# cyt2cl register map
Vendor: Cypress Semiconductor; Series: cyt2cl; File version: 1.0
CPU: CM4 r0p1, little endian, MPU, FPU, VTOR, 3 interrupt priority bits
Registers are 32-bit, read-write, reset 0x0 unless marked. A register's access mark holds for its fields unless they carry their own. Offsets are from the block's base; [hi:lo] are bit positions; lines under a group give offsets from that group; 'fields as' and 'values as' point back to an identical list.

## FLASHC — Flash controller
Base 0x40240000
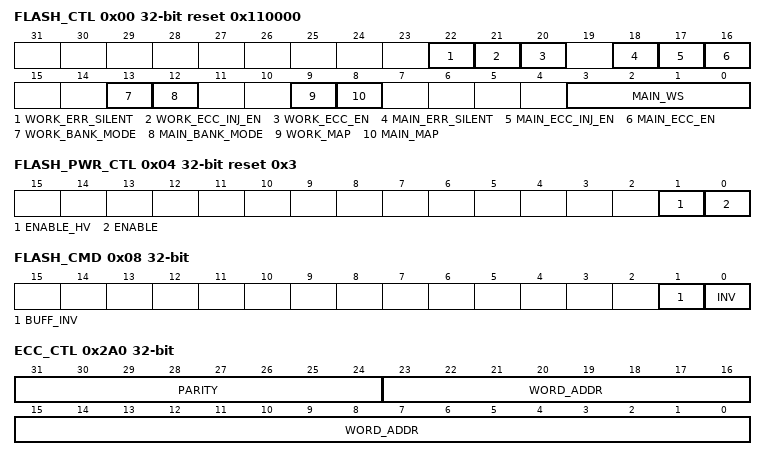
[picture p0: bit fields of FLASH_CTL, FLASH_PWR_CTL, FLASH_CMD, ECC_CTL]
0x00 FLASH_CTL reset 0x110000 — Control
  [22] WORK_ERR_SILENT — Specifies bus transfer behavior for a non-recoverable error on the FLASH macro work interface (either a non-correctable ECC error, a FLASH macro work interface internal error, a FLASH macro work interface memory hole access): 0: Bus transfer has a bus error. 1: Bus transfer does NOT have a bus error; i.e. the error is 'silent' In either case, the erroneous FLASH macro data is returned by the bus master interface. The erroneous data is NOT placed in a bus master interface's cache and/or buffer. This field is ONLY used by CPU (and debug i.e. SYS_AP/CM0_AP/CM4_AP) bus transfers. Non-CPU bus transfers always have a bus transfer with a bus error, in case of a non-recoverable error. Note: All CPU bus masters have dedicated status registers (CM0_STATUS and CM4_STATUS) to register the occurrence of FLASH macro work interface internal errors (non-correctable ECC errors and memory hole errors are NOT registered). Note: fault reporting can be used to identify the error that occurred: - FLASH macro work interface internal error. - FLASH macro work interface non-recoverable ECC error. - FLASH macro work interface recoverable ECC error. - FLASH macro work interface memory hole error.
  [21] WORK_ECC_INJ_EN — Enable error injection for FLASH work interface. When'1', the parity (ECC_CTL.PARITY[6:0]) is used for a load from the ECC_CTL.WORD_ADDR[23:0] word address.
  [20] WORK_ECC_EN — Enable ECC checking for FLASH work interface: 0: Disabled. ECC checking/reporting on FLASH work interface is disabled. No correctable or non-correctable faults are reported. 1: Enabled.
  [18] MAIN_ERR_SILENT — Specifies bus transfer behavior for a non-recoverable error on the FLASH macro main interface (either a non-correctable ECC error, a FLASH macro main interface internal error, a FLASH macro main interface memory hole access): 0: Bus transfer has a bus error. 1: Bus transfer does NOT have a bus error; i.e. the error is 'silent' In either case, the erroneous FLASH macro data is returned by the bus master interface. The erroneous data is NOT placed in a bus master interface's cache and/or buffer. This field is ONLY used by CPU (and debug i.e. SYS_AP/CM0_AP/CM4_AP) bus transfers. Non-CPU bus transfers always have a bus transfer with a bus error, in case of a non-recoverable error. Note: All CPU bus masters have dedicated status registers (CM0_STATUS and CM4_STATUS) to register the occurrence of FLASH macro main interface internal errors (non-correctable ECC errors and memory hole errors are NOT registered). Note: fault reporting can be used to identify the error that occurred: - FLASH macro main interface internal error. - FLASH macro main interface non-recoverable ECC error. - FLASH macro main interface recoverable ECC error. - FLASH macro main interface memory hole error.
  [17] MAIN_ECC_INJ_EN — Enable error injection for FLASH main interface. When'1', the parity (ECC_CTL.PARITY[7:0]) is used for a load from the ECC_CTL.WORD_ADDR[23:0] word address.
  [16] MAIN_ECC_EN — Enable ECC checking for FLASH main interface: 0: Disabled. ECC checking/reporting on FLASH main interface is disabled. No correctable or non-correctable faults are reported. 1: Enabled.
  [13] WORK_BANK_MODE — Specifies bank mode of FLASH macro work array. 0: Single bank mode. 1: Dual bank mode.
  [12] MAIN_BANK_MODE — Specifies bank mode of FLASH macro main array. 0: Single bank mode. 1: Dual bank mode.
  [9] WORK_MAP — Specifies mapping of FLASH macro work array. 0: Mapping A. 1: Mapping B. This field is only used when WORK_BANK_MODE is '1' (dual bank mode).
  [8] MAIN_MAP — Specifies mapping of FLASH macro main array. 0: Mapping A. 1: Mapping B. This field is only used when MAIN_BANK_MODE is '1' (dual bank mode).
  [3:0] MAIN_WS — FLASH macro main interface wait states: '0': 0 wait states. ... '15': 15 wait states
0x04 FLASH_PWR_CTL reset 0x3 — Flash power control
  [1] ENABLE_HV — Enables HV power to the flash memory
  [0] ENABLE — Enables power to the flash memory
0x08 FLASH_CMD — Command
  [1] BUFF_INV — Invalidation of ALL buffers (does not invalidate the caches). SW writes a '1' to clear the buffers. HW sets this field to '0' when the operation is completed. The operation takes a maximum of three clock cycles on the slowest of the clk_slow and clk_fast clocks. Note: the caches only capture FLASH macro main array data. Therefore, invalidating just the buffers (BUFF_INV) does not invalidate captures main array data in the caches.
  [0] INV — Invalidation of ALL caches (for CM0+ and CM4) and ALL buffers. SW writes a '1' to clear the caches. HW sets this field to '0' when the operation is completed. The operation takes a maximum of three clock cycles on the slowest of the clk_slow and clk_fast clocks. The caches' LRU structures are also reset to their default state.
0x2A0 ECC_CTL — ECC control
  [31:24] PARITY — ECC parity to use for ECC error injection at address WORD_ADDR. - For cache SRAM ECC, the 7-bit parity PARITY[6:0] is for a 32-bit word. - For FLASH main interface ECC, the 8-bit parity PARITY[7:0] is for a 64-bit word. - For FLASH work interface ECC, the 7-bit parity PARITY[6:0] is for a 32-bit word.
  [23:0] WORD_ADDR — Specifies the word address where an error will be injected. - For cache SRAM ECC, the word address WORD_ADDR[23:0] is device address A[25:2]. On a FLASH macro refill to this word address and when the corresponding CM0/4_CA_CTL.RAM_ECC_INJ_EN bit is '1', the parity (PARITY[6:0]) is injected and stored in the cache. - For FLASH main interface ECC, the word address WORD_ADDR[23:0] is device address A[26:3]. On a FLASH main interface read and when FLASH_CTL.MAIN_ECC_INJ_EN bit is '1', the parity (PARITY[7:0]) replaces the FLASH macro parity (FLASH main interface read path is manipulated). - For FLASH work interface ECC, the word address WORD_ADDR[23:0] is device address A[24:2]. On a FLASH work interface read and when FLASH_CTL.WORK_ECC_INJ_EN bit is '1', the parity (PARITY[6:0]) replaces the FLASH macro parity (FLASH work interface read path is manipulated).
0x2B0 FM_SRAM_ECC_CTL0 — eCT Flash SRAM ECC control 0
  [31:0] ECC_INJ_DATA — 32-bit data for ECC error injection test of eCT Flash SRAM ECC logic.
0x2B4 FM_SRAM_ECC_CTL1 — eCT Flash SRAM ECC control 1
  [6:0] ECC_INJ_PARITY — 7-bit parity for ECC error injection test of eCT Flash SRAM ECC logic.
0x2B8 FM_SRAM_ECC_CTL2 ro — eCT Flash SRAM ECC control 2
  [31:0] CORRECTED_DATA — 32-bit corrected data output of the ECC syndrome logic.
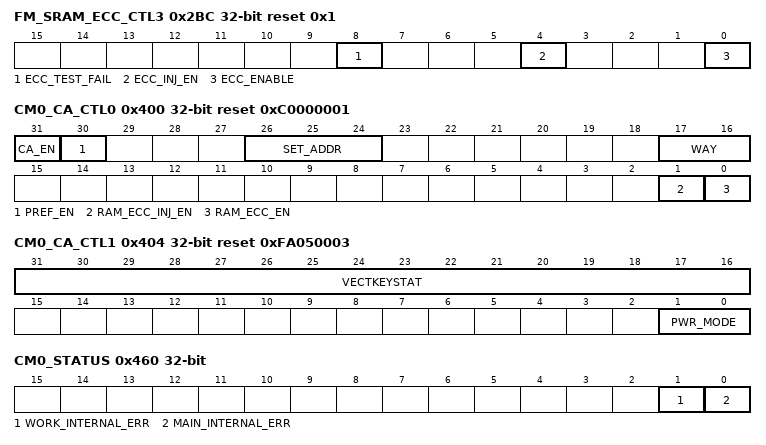
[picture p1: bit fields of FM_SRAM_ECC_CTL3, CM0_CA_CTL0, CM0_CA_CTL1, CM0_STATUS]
0x2BC FM_SRAM_ECC_CTL3 reset 0x1 — eCT Flash SRAM ECC control 3
  [8] ECC_TEST_FAIL ro — Status of ECC test. 1 : ECC test failed because eCT Flash macro is busy and using the SRAM. 0: ECC was performed.
  [4] ECC_INJ_EN — eCT Flash SRAM ECC error injection test enable. Follow the steps below for ECC logic test: 1. Write corrupted or uncorrupted 39-bit data to FM_SRAM_ECC_CTL0/1 registers. 2. Set the ECC_INJ_EN bit to '1'. 3. Confirm that the bit ECC_TEST_FAIL is '0'. If this is not the case, start over at item 1 because the eCT Flash was not idle. 4. Check the corrected data in FM_SRAM_ECC_CTL2. 5. Confirm that fault was reported to fault structure, and check syndrome (only applicable if corrupted data was written in step 1). 6. If not finished, start over at 1 with different data.
  [0] ECC_ENABLE — ECC generation/check enable for eCT Flash SRAM memory.
0x400 CM0_CA_CTL0 reset 0xC0000001 — CM0+ cache control
  [31] CA_EN — Cache enable: 0: Disabled. The cache tag valid bits are reset to '0's and the cache LRU information is set to '1's (making way 0 the LRU way and way 3 the MRU way). 1: Enabled.
  [30] PREF_EN — Prefetch enable: 0: Disabled. 1: Enabled. Prefetching requires the cache to be enabled; i.e. ENABLED is '1'.
  [26:24] SET_ADDR — Specifies the cache set for which cache information is provided in CM0_CA_STATUS0/1/2.
  [17:16] WAY — Specifies the cache way for which cache information is provided in CM0_CA_STATUS0/1/2.
  [1] RAM_ECC_INJ_EN — Enable error injection for cache. When '1', the parity (ECC_CTL.PARITY[6:0]) is used when a refill is done from the FLASH macro to the ECC_CTL.WORD_ADDR[23:0] word address.
  [0] RAM_ECC_EN — Enable ECC checking for cache accesses: 0: Disabled. 1: Enabled.
0x404 CM0_CA_CTL1 reset 0xFA050003 — CM0+ cache control
  [31:16] VECTKEYSTAT ro — Register key (to prevent accidental writes). - Should be written with a 0x05fa key value for the write to take effect. - Always reads as 0xfa05. Note: Although the SW attribute for this field says ''R', SW need to write the key 0x05fa in this field for this register write to happen. This is a built in protection provided to prevent accidental writes from SW.
  [1:0] PWR_MODE — Specifies power mode for CM0 cache. The following sequnece should be followed for turning OFF/ON the cache SRAM. Turn OFF sequence: a) Write CM0_CA_CTL0 to disable cache. b) Write CM0_CA_CTL1 to turn OFF cache SRAM. Turn ON sequence: a) Write CM0_CA_CTL1 to turn ON cache SRAM. b) Delay to allow power up of cache SRAM. Delay should be at a minimum of CM0_CA_CTL2.PWRUP_DELAY CLK_SLOW clock cycles. c) Write CM0_CA_CTL0 to enable cache.
    0=OFF (Power OFF the CM0 cache, no retain); 1=RSVD (Undefined); 2=RETAINED (Put the CM0 cache in retained mode); 3=ENABLED (Enable/Turn ON the CM0 cache SRAM.)
0x408 CM0_CA_CTL2 reset 0x12C — CM0+ cache control
  [9:0] PWRUP_DELAY — Number clock cycles delay needed after power domain power up
0x440 CM0_CA_STATUS0 ro — CM0+ cache status 0
  [31:0] VALID32 — Sixteen valid bits of the cache line specified by CM0_CA_CTL.WAY and CM0_CA_CTL.SET_ADDR.
0x444 CM0_CA_STATUS1 ro reset not defined — CM0+ cache status 1
  [31:0] TAG — Cache line address of the cache line specified by CM0_CA_CTL.WAY and CM0_CA_CTL.SET_ADDR.
0x448 CM0_CA_STATUS2 ro reset not defined — CM0+ cache status 2
  [5:0] LRU — Six bit LRU representation of the cache set specified by CM0_CA_CTL.SET_ADDR. The encoding of the field is as follows ('X_LRU_Y' indicates that way X is Less Recently Used than way Y): Bit 5: 0_LRU_1: way 0 less recently used than way 1. Bit 4: 0_LRU_2. Bit 3: 0_LRU_3. Bit 2: 1_LRU_2. Bit 1: 1_LRU_3. Bit 0: 2_LRU_3.
0x460 CM0_STATUS — CM0+ interface status
  [1] WORK_INTERNAL_ERR — See CM0_STATUS.MAIN_INTERNAL_ERROR.
  [0] MAIN_INTERNAL_ERR — Specifies/registers the occurrence of a FLASH macro main interface internal error (typically the result of a read access while a program erase operation is ongoing) as a result of a CM0+ access (or debug access via SYS_AP/CM0_AP). SW clears this field to '0'. HW sets this field to '1' on a FLASH macro main interface internal error. Typically, SW reads this field after a code section to detect the occurrence of an error. Note: this field is independent of FLASH_CTL.MAIN_ERR_SILENT.
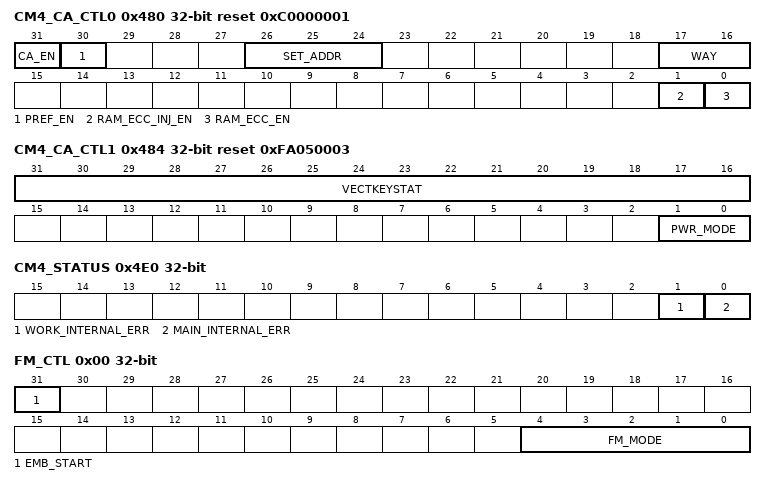
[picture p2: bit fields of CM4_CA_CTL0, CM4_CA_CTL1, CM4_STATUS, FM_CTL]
0x480 CM4_CA_CTL0 reset 0xC0000001 — CM4 cache control
  [31] CA_EN — Cache enable: 0: Disabled. The cache tag valid bits are reset to '0's and the cache LRU information is set to '1's (making way 0 the LRU way and way 3 the MRU way). 1: Enabled.
  [30] PREF_EN — Prefetch enable: 0: Disabled. 1: Enabled. Prefetching requires the cache to be enabled; i.e. ENABLED is '1'.
  [26:24] SET_ADDR — Specifies the cache set for which cache information is provided in CM4_CA_STATUS0/1/2.
  [17:16] WAY — Specifies the cache way for which cache information is provided in CM4_CA_STATUS0/1/2.
  [1] RAM_ECC_INJ_EN — See CM0_CA_CTL.
  [0] RAM_ECC_EN — See CM0_CA_CTL.
0x484 CM4_CA_CTL1 reset 0xFA050003 — CM4 cache control
  [31:16] VECTKEYSTAT ro — Register key (to prevent accidental writes). - Should be written with a 0x05fa key value for the write to take effect. - Always reads as 0xfa05. Note: Although the SW attribute for this field says ''R', SW need to write the key 0x05fa in this field for this register write to happen. This is a built in protection provided to prevent accidental writes from SW.
  [1:0] PWR_MODE — Specifies power mode for CM4 cache. The following sequnece should be followed for truning OFF/ON the cache SRAM. Turn OFF sequence: a) Write CM4_CA_CTL0 to disable cache. b) Write CM4_CA_CTL1 to turn OFF cache SRAM. Turn ON sequence: a) Write CM4_CA_CTL1 to turn ON cache SRAM. b) Delay to allow power up of cache SRAM. Delay should be at a minimum of CM4_CA_CTL2.PWRUP_DELAY CLK_SLOW clock cycles. c) Write CM4_CA_CTL0 to enable cache.
    0=OFF (Power OFF the CM4 cache, not retained.); 1=RSVD (Undefined); 2=RETAINED (Put the CM4 cache in retained mode.); 3=ENABLED (Enable/Turn ON the CM4 cache.)
0x488 CM4_CA_CTL2 reset 0x12C — CM4 cache control
  fields as CM0_CA_CTL2
0x4C0 CM4_CA_STATUS0 ro — CM4 cache status 0
  [31:0] VALID32 — See CM0_CA_STATUS0.
0x4C4 CM4_CA_STATUS1 ro reset not defined — CM4 cache status 1
  [31:0] TAG — See CM0_CA_STATUS1.
0x4C8 CM4_CA_STATUS2 ro reset not defined — CM4 cache status 2
  [5:0] LRU — See CM0_CA_STATUS2.
0x4E0 CM4_STATUS — CM4 interface status
  [1] WORK_INTERNAL_ERR — See CM4_STATUS.MAIN_INTERNAL_ERROR.
  [0] MAIN_INTERNAL_ERR — Specifies/registers the occurrence of a FLASH macro main interface internal error (typically the result of a read access while a program erase operation is ongoing) as a result of a CM4 access (or debug access via SYS_AP/CM4_AP). SW clears this field to '0'. HW sets this field to '1' on a FLASH macro main interface internal error. Typically, SW reads this field after a code section to detect the occurrence of an error. Note: this field is independent of FLASH_CTL.MAIN_ERR_SILENT.
0x500 CRYPTO_BUFF_CTL reset 0x40000000 — Cryptography buffer control
  [30] PREF_EN — Prefetch enable: 0: Disabled. 1: Enabled. A prefetch will be done when there is read 'hit' on the last 32-bit word of the buffer. For eCT work Flash, prefetch will not be done.
0x580 DW0_BUFF_CTL reset 0x40000000 — Datawire 0 buffer control
  [30] PREF_EN — See CRYPTO_BUFF_CTL.
0x600 DW1_BUFF_CTL reset 0x40000000 — Datawire 1 buffer control
  [30] PREF_EN — See CRYPTO_BUFF_CTL.
0x680 DMAC_BUFF_CTL reset 0x40000000 — DMA controller buffer control
  [30] PREF_EN — See CRYPTO_BUFF_CTL.
0x700 EXT_MS0_BUFF_CTL reset 0x40000000 — External master 0 buffer control
  [30] PREF_EN — See CRYPTO_BUFF_CTL.
0x780 EXT_MS1_BUFF_CTL reset 0x40000000 — External master 1 buffer control
  [30] PREF_EN — See CRYPTO_BUFF_CTL.
0xF000 FM_CTL_ECT group — Flash Macro Registers
  0x00 FM_CTL — Flash Macro Control
    [31] EMB_START — '0': not active '1': starts the actual embedded operation
    [4:0] FM_MODE — Flash macro mode selection: d0: Read/Idle - Normal mode, read array enabled d1: Not Used - the 1st analog POR is done by enable/enable_hv d2 - POR FUR Download - Downloads critical Flash initialization data from OTP (BG, rd, redu, etc....) d3 - POR IRAM MMR Download - Downloads from OTP region the MMR / IRAM into to the 8051 RDL shadows d4 - POR SW Download - Downloads from OTP region the SW code into to the 8051 MCU SRAM d5 - POR Code_Work Prepare - Loads the Code and Work Flash MG's to be ready for user mode operation d6 - Not Used d7 - Program 32b (WORK) - Used as program confirm command for 32 (Work) bits program d8 - Program 64b (CODE) - Used as program confirm command for 64 (Code) bits program d9 - Program 256b (CODE) - Used as program confirm command for 256 (Code) bits program d10: Program Page (CODE) - Used as program confirm command for page program for Code flash d11: Not Used d12 - Sector Erase - Erase for all kinds of sectors (Code/Work/SMS) d13 - Blank check Entry (UBC) d14 - Blank Check Read 32bit (WORK) - Blank check mode d15 - Blank check Exit d16 - Not Used d17 - Erase Suspend - Suspend command to the Erase operation d18 - Erase Resume - Resume command to Erase suspended operation d19 - Not Used d20- Not Used d21- Not Used d22- Not Used d23- Not Used d24- Not Used d25- Not Used d26- Not Used d27- Not Used d28- Not Used d29- Not Used d30: Not Used d31: Not Used
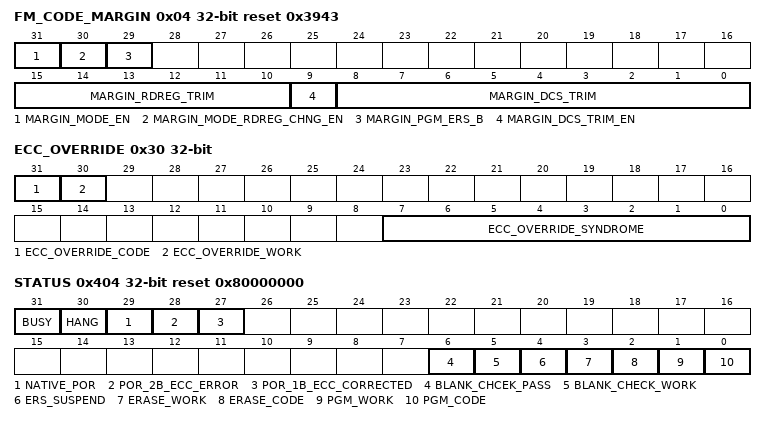
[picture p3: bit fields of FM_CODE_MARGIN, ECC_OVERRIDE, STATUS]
  0x04 FM_CODE_MARGIN reset 0x3943 — Flash Macro Margin Mode on Code Flash
    [31] MARGIN_MODE_EN — when set puts the s40ect Flash IP In Margin mode
    [30] MARGIN_MODE_RDREG_CHNG_EN — when set will also use the MARGIN_RDREG_TRIM from above. Default is not to use
    [29] MARGIN_PGM_ERS_B — 0: ERS Margin is checked 1: PGM Margin is checked
    [15:10] MARGIN_RDREG_TRIM — rdreg_c trim to be used in Margin mode if enabled by MARGIN_MODE_RDREG_CHNG_EN
    [9] MARGIN_DCS_TRIM_EN — 0: internal device defaults used from Margin reads reference current 1: MARGIN_DCS_TRIM configuration is used during Margin read
    [8:0] MARGIN_DCS_TRIM — see above table to set the DCS reference current value to be used during Margin mode. (default set to 5uS = 0x143) which gives a Margin to the Erase side. 7uA would probably be used for Margin to the PGM side
  0x08 FM_ADDR wo — Flash Macro Address
    [31:0] FM_ADDR — Code or Work Flash Address to be used during write operations (PGM/ERS)
  0x20 INTR — Interrupt
    [0] INTR — Set to '1', when event is detected. Write INTR field with '1', to clear bit. Write INTR_SET field with '1', to set bit.
  0x24 INTR_SET — Interrupt Set
    [0] INTR_SET — Write INTR_SET field with '1' to set corresponding INTR field (a write of '0' has no effect).
  0x28 INTR_MASK — Interrupt Mask
    [0] INTR_MASK — Mask for corresponding field in the INTR register
  0x2C INTR_MASKED ro — Interrupt Masked
    [0] INTR_MASKED — Logical and of corresponding request and mask fields.
  0x30 ECC_OVERRIDE wo — ECC Data In override information and control bits
    [31] ECC_OVERRIDE_CODE — 0: no override. Using internal ECC engine to calculate the ECC of the Code Flash
    [30] ECC_OVERRIDE_WORK — 0: no override. Using internal ECC engine to calculate the ECC of the Work Flash
    [7:0] ECC_OVERRIDE_SYNDROME — The override syndrome itself to be used in case one of the enables are set. It will take [7:0] in the case of Code flash and [6:0] in the case of work flash, to bypass the internal generated syndrome
  0x40 FM_DATA wo — Flash macro data_in[31 to 0] both Code and Work Flash
    [31:0] FM_DATA — Pgm command data in going to the internal write buffer (WBUF).
  0x64 BOOKMARK — Bookmark register - keeps the current FW HV seq
    [31:0] BOOKMARK — Used by FW. Keeps the Current HV cycle sequence
  0x400 MAIN_FLASH_SAFETY — Main (Code) Flash Security enable
    [0] MAINFLASHWRITEENABLE — '0': Main Flash embedded operations are blocked '1': Main Flash embedded operations are enabled
  0x404 STATUS ro reset 0x80000000 — Status read from Flash Macro
    [31] BUSY — Whenever the device is in embedded mode the RDY goes low. Should be the same as c_interrupt pin of the IP (but inverted) 1: busy in embedded 0: rdy (high also in erase suspend)
    [30] HANG — After embedded operation (pgm/erase) this flag will tell if it was successful or failed 0: PASS 1: FAIL
    [29] NATIVE_POR — Indicates a Native Flash state (UV) or sorted one. Valid only after 2nd phase of POR (FUR DOWNLOAD). Comment: not a retained flop, therefore reset (rst_hf_act_n) puts it back to 0. If Set it is not cleaned till additional POR (rst_hf_ac_t) 0: SORTED DEVICE (Non - Native) 1: NATIVE
    [28] POR_2B_ECC_ERROR — Indicates an internal ECC error of 2b while downloading info in POR from NVM to VM. Valid after 2nd, 3rd and 4th POR phases (FUR, IREM & MMR, SW DOWNLOAD). If Set it is not cleaned till additional POR (rst_hf_ac_t) 0: No error 1: ECC 2b Error in POR
    [27] POR_1B_ECC_CORRECTED — Indicates internal ECC found 1b error while downloading info in POR from NVM to VM and fixed it. Valid after 2nd, 3rd and 4th POR phases (FUR, IREM & MMR, SW DOWNLOAD). If Set it is not cleaned till additional POR (rst_hf_ac_t) 0: No error 1: 1b ECC Error corrected in POR
    [6] BLANK_CHCEK_PASS — Indicates the Blank check command result is PASS (Blank) 0: Not Blank 1: Blank (PASS)
    [5] BLANK_CHECK_WORK — Indicates if Blank Check mode is currently running on the work flash 0: not running 1: running
    [4] ERS_SUSPEND — Indicates if Erase operation (Code/Work) is currently being suspended 0: not suspended 1: suspended
    [3] ERASE_WORK — Indicates if active Erase operation to the Work flash is taking place 0: not running 1: running
    [2] ERASE_CODE — Indicates if active Erase operation to the Code flash is taking place 0: not running 1: running
    [1] PGM_WORK — Indicates if active PGM operation to the Work flash is taking place 0: not running 1: running
    [0] PGM_CODE — Indicates if active PGM operation to the Code flash is taking place 0: not running 1: running
  0x500 WORK_FLASH_SAFETY — Work Flash Security enable
    [0] WORKFLASHWRITEENABLE — 0: Work Flash embedded operations are blocked 1: Work Flash embedded operations are enabled

## Notices in the file
Copyright 2016-2019, Cypress Semiconductor Corporation.  All rights reserved.
You may use this file only in accordance with the license, terms, conditions,
disclaimers, and limitations in the end user license agreement accompanying
the software package with which this file was provided.
